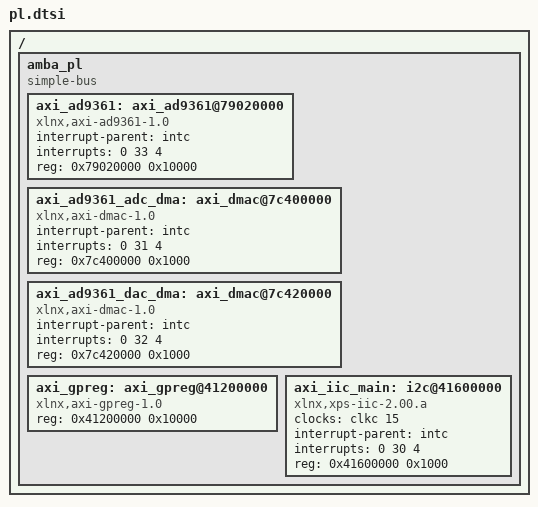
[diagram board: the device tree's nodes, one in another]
/*
 * CAUTION: This file is automatically generated by Xilinx.
 * Version:  
 * Today is: Wed Aug  7 13:27:27 2019
 */


/ {
	amba_pl: amba_pl {
		#address-cells = <1>;
		#size-cells = <1>;
		compatible = "simple-bus";
		ranges ;
		axi_ad9361: axi_ad9361@79020000 {
			compatible = "xlnx,axi-ad9361-1.0";
			interrupt-names = "gps_pps_irq";
			interrupt-parent = <&intc>;
			interrupts = <0 33 4>;
			reg = <0x79020000 0x10000>;
		};
		axi_ad9361_adc_dma: axi_dmac@7c400000 {
			compatible = "xlnx,axi-dmac-1.0";
			interrupt-names = "irq";
			interrupt-parent = <&intc>;
			interrupts = <0 31 4>;
			reg = <0x7c400000 0x1000>;
		};
		axi_ad9361_dac_dma: axi_dmac@7c420000 {
			compatible = "xlnx,axi-dmac-1.0";
			interrupt-names = "irq";
			interrupt-parent = <&intc>;
			interrupts = <0 32 4>;
			reg = <0x7c420000 0x1000>;
		};
		axi_gpreg: axi_gpreg@41200000 {
			compatible = "xlnx,axi-gpreg-1.0";
			reg = <0x41200000 0x10000>;
		};
		axi_iic_main: i2c@41600000 {
			#address-cells = <1>;
			#size-cells = <0>;
			clock-names = "s_axi_aclk";
			clocks = <&clkc 15>;
			compatible = "xlnx,xps-iic-2.00.a";
			interrupt-names = "iic2intc_irpt";
			interrupt-parent = <&intc>;
			interrupts = <0 30 4>;
			reg = <0x41600000 0x1000>;
		};
	};
};
